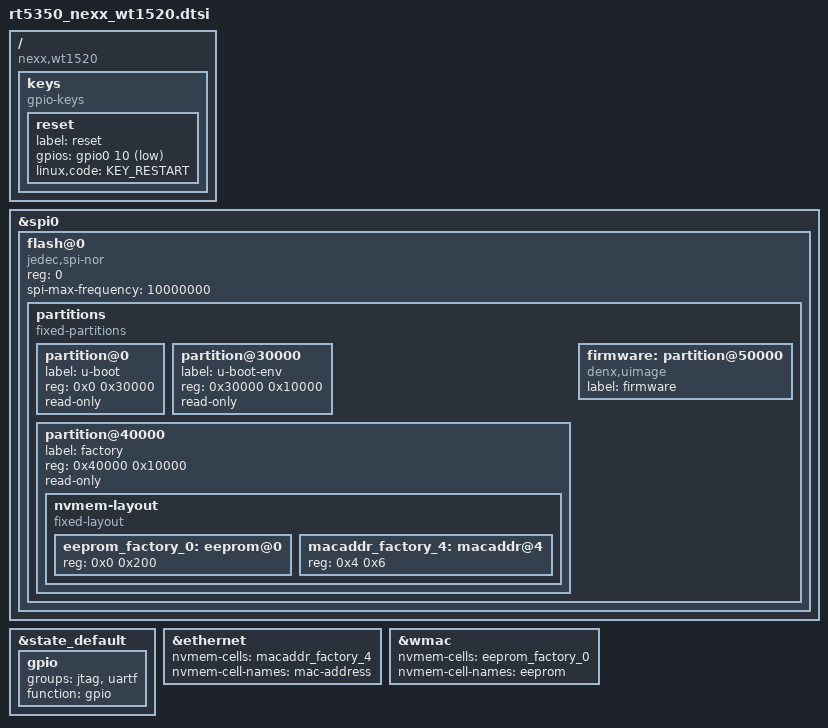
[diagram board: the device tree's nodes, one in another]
#include "rt5350.dtsi"

#include <dt-bindings/gpio/gpio.h>
#include <dt-bindings/input/input.h>

/ {
	compatible = "nexx,wt1520", "ralink,rt5350-soc";

	keys {
		compatible = "gpio-keys";

		reset {
			label = "reset";
			gpios = <&gpio0 10 GPIO_ACTIVE_LOW>;
			linux,code = <KEY_RESTART>;
		};
	};
};

&spi0 {
	status = "okay";

	flash@0 {
		compatible = "jedec,spi-nor";
		reg = <0>;
		spi-max-frequency = <10000000>;

		partitions {
			compatible = "fixed-partitions";
			#address-cells = <1>;
			#size-cells = <1>;

			partition@0 {
				label = "u-boot";
				reg = <0x0 0x30000>;
				read-only;
			};

			partition@30000 {
				label = "u-boot-env";
				reg = <0x30000 0x10000>;
				read-only;
			};

			partition@40000 {
				label = "factory";
				reg = <0x40000 0x10000>;
				read-only;

				nvmem-layout {
					compatible = "fixed-layout";
					#address-cells = <1>;
					#size-cells = <1>;

					eeprom_factory_0: eeprom@0 {
						reg = <0x0 0x200>;
					};

					macaddr_factory_4: macaddr@4 {
						reg = <0x4 0x6>;
					};
				};
			};

			firmware: partition@50000 {
				compatible = "denx,uimage";
				label = "firmware";
				/* reg property is set based on flash size in DTS files */
			};
		};
	};
};

&state_default {
	gpio {
		groups = "jtag", "uartf";
		function = "gpio";
	};
};

&ethernet {
	nvmem-cells = <&macaddr_factory_4>;
	nvmem-cell-names = "mac-address";
};

&wmac {
	nvmem-cells = <&eeprom_factory_0>;
	nvmem-cell-names = "eeprom";
};
